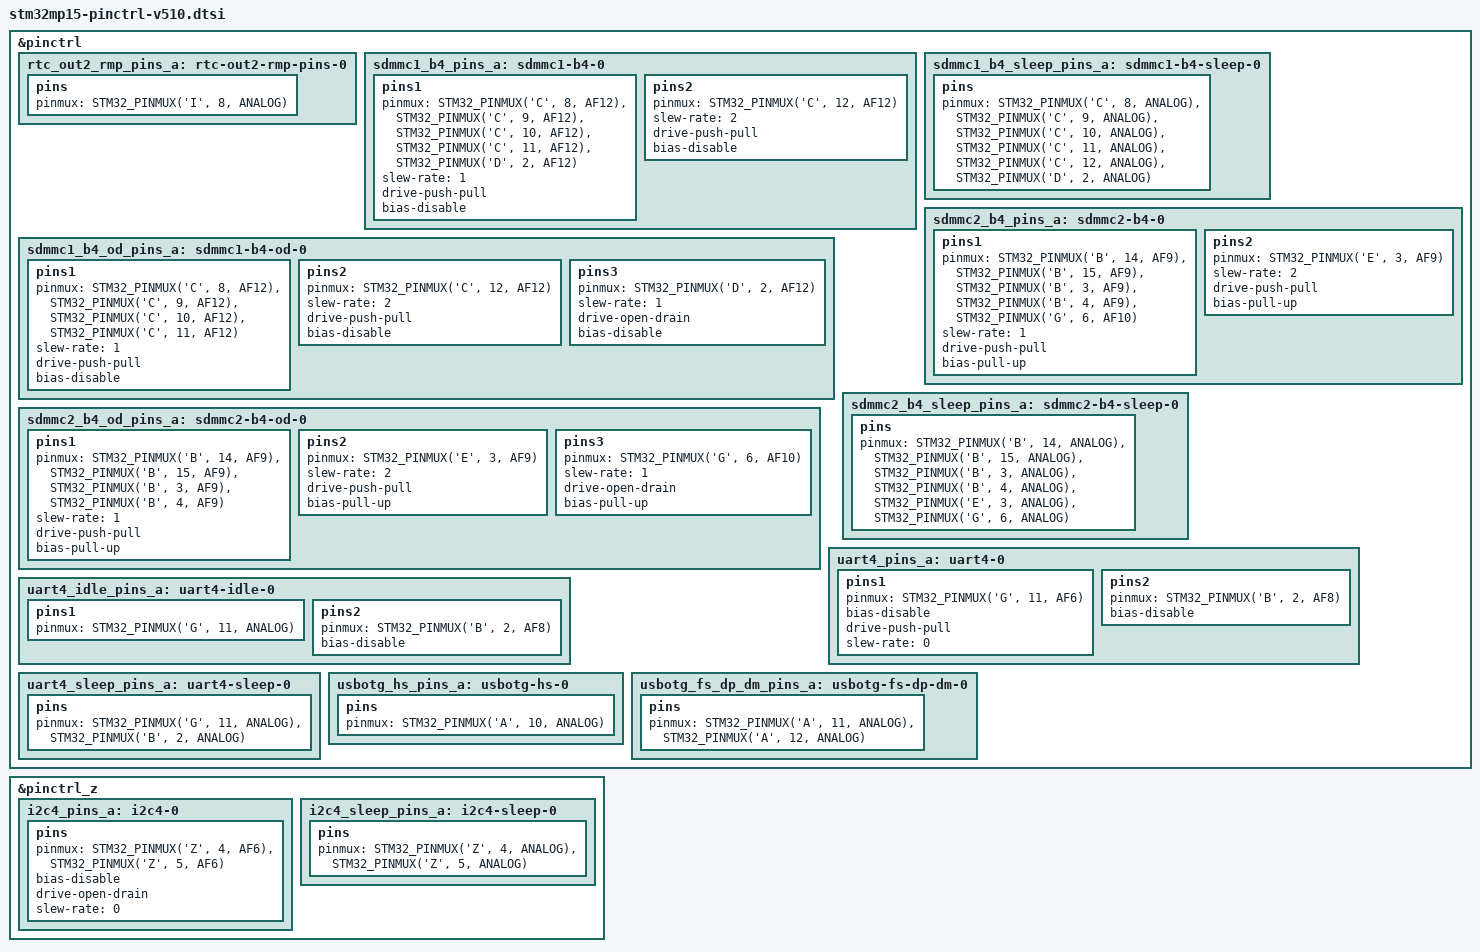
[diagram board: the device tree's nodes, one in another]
// SPDX-License-Identifier: (GPL-2.0+ OR BSD-3-Clause)
/*
 * Copyright (C) STMicroelectronics 2017 - All Rights Reserved
 * Author: Ludovic Barre <ludovic.barre@st.com> for STMicroelectronics.
 */
#include <dt-bindings/pinctrl/stm32-pinfunc.h>

&pinctrl {

	rtc_out2_rmp_pins_a: rtc-out2-rmp-pins-0 {
		pins {
			pinmux = <STM32_PINMUX('I', 8, ANALOG)>; /* RTC_OUT2_RMP */
		};
	};



	sdmmc1_b4_pins_a: sdmmc1-b4-0 {
		pins1 {
			pinmux = <STM32_PINMUX('C', 8, AF12)>, /* SDMMC1_D0 */
				 <STM32_PINMUX('C', 9, AF12)>, /* SDMMC1_D1 */
				 <STM32_PINMUX('C', 10, AF12)>, /* SDMMC1_D2 */
				 <STM32_PINMUX('C', 11, AF12)>, /* SDMMC1_D3 */
				 <STM32_PINMUX('D', 2, AF12)>; /* SDMMC1_CMD */
			slew-rate = <1>;
			drive-push-pull;
			bias-disable;
		};
		pins2 {
			pinmux = <STM32_PINMUX('C', 12, AF12)>; /* SDMMC1_CK */
			slew-rate = <2>;
			drive-push-pull;
			bias-disable;
		};
	};

	sdmmc1_b4_od_pins_a: sdmmc1-b4-od-0 {
		pins1 {
			pinmux = <STM32_PINMUX('C', 8, AF12)>, /* SDMMC1_D0 */
				 <STM32_PINMUX('C', 9, AF12)>, /* SDMMC1_D1 */
				 <STM32_PINMUX('C', 10, AF12)>, /* SDMMC1_D2 */
				 <STM32_PINMUX('C', 11, AF12)>; /* SDMMC1_D3 */
			slew-rate = <1>;
			drive-push-pull;
			bias-disable;
		};
		pins2 {
			pinmux = <STM32_PINMUX('C', 12, AF12)>; /* SDMMC1_CK */
			slew-rate = <2>;
			drive-push-pull;
			bias-disable;
		};
		pins3 {
			pinmux = <STM32_PINMUX('D', 2, AF12)>; /* SDMMC1_CMD */
			slew-rate = <1>;
			drive-open-drain;
			bias-disable;
		};
	};

	sdmmc1_b4_sleep_pins_a: sdmmc1-b4-sleep-0 {
		pins {
			pinmux = <STM32_PINMUX('C', 8, ANALOG)>, /* SDMMC1_D0 */
				 <STM32_PINMUX('C', 9, ANALOG)>, /* SDMMC1_D1 */
				 <STM32_PINMUX('C', 10, ANALOG)>, /* SDMMC1_D2 */
				 <STM32_PINMUX('C', 11, ANALOG)>, /* SDMMC1_D3 */
				 <STM32_PINMUX('C', 12, ANALOG)>, /* SDMMC1_CK */
				 <STM32_PINMUX('D', 2, ANALOG)>; /* SDMMC1_CMD */
		};
	};

	sdmmc2_b4_pins_a: sdmmc2-b4-0 {
		pins1 {
			pinmux = <STM32_PINMUX('B', 14, AF9)>, /* SDMMC2_D0 */
				 <STM32_PINMUX('B', 15, AF9)>, /* SDMMC2_D1 */
				 <STM32_PINMUX('B', 3, AF9)>, /* SDMMC2_D2 */
				 <STM32_PINMUX('B', 4, AF9)>, /* SDMMC2_D3 */
				 <STM32_PINMUX('G', 6, AF10)>; /* SDMMC2_CMD */
			slew-rate = <1>;
			drive-push-pull;
			bias-pull-up;
		};
		pins2 {
			pinmux = <STM32_PINMUX('E', 3, AF9)>; /* SDMMC2_CK */
			slew-rate = <2>;
			drive-push-pull;
			bias-pull-up;
		};
	};

	sdmmc2_b4_od_pins_a: sdmmc2-b4-od-0 {
		pins1 {
			pinmux = <STM32_PINMUX('B', 14, AF9)>, /* SDMMC2_D0 */
				 <STM32_PINMUX('B', 15, AF9)>, /* SDMMC2_D1 */
				 <STM32_PINMUX('B', 3, AF9)>, /* SDMMC2_D2 */
				 <STM32_PINMUX('B', 4, AF9)>; /* SDMMC2_D3 */
			slew-rate = <1>;
			drive-push-pull;
			bias-pull-up;
		};
		pins2 {
			pinmux = <STM32_PINMUX('E', 3, AF9)>; /* SDMMC2_CK */
			slew-rate = <2>;
			drive-push-pull;
			bias-pull-up;
		};
		pins3 {
			pinmux = <STM32_PINMUX('G', 6, AF10)>; /* SDMMC2_CMD */
			slew-rate = <1>;
			drive-open-drain;
			bias-pull-up;
		};
	};

	sdmmc2_b4_sleep_pins_a: sdmmc2-b4-sleep-0 {
		pins {
			pinmux = <STM32_PINMUX('B', 14, ANALOG)>, /* SDMMC2_D0 */
				 <STM32_PINMUX('B', 15, ANALOG)>, /* SDMMC2_D1 */
				 <STM32_PINMUX('B', 3, ANALOG)>, /* SDMMC2_D2 */
				 <STM32_PINMUX('B', 4, ANALOG)>, /* SDMMC2_D3 */
				 <STM32_PINMUX('E', 3, ANALOG)>, /* SDMMC2_CK */
				 <STM32_PINMUX('G', 6, ANALOG)>; /* SDMMC2_CMD */
		};
	};


	uart4_pins_a: uart4-0 {
		pins1 {
			pinmux = <STM32_PINMUX('G', 11, AF6)>; /* UART4_TX */
			bias-disable;
			drive-push-pull;
			slew-rate = <0>;
		};
		pins2 {
			pinmux = <STM32_PINMUX('B', 2, AF8)>; /* UART4_RX */
			bias-disable;
		};
	};

	uart4_idle_pins_a: uart4-idle-0 {
		pins1 {
			pinmux = <STM32_PINMUX('G', 11, ANALOG)>; /* UART4_TX */
		};
		pins2 {
			pinmux = <STM32_PINMUX('B', 2, AF8)>; /* UART4_RX */
			bias-disable;
		};
	};

	uart4_sleep_pins_a: uart4-sleep-0 {
		pins {
			pinmux = <STM32_PINMUX('G', 11, ANALOG)>, /* UART4_TX */
				 <STM32_PINMUX('B', 2, ANALOG)>; /* UART4_RX */
		};
	};

	usbotg_hs_pins_a: usbotg-hs-0 {
		pins {
			pinmux = <STM32_PINMUX('A', 10, ANALOG)>; /* OTG_ID */
		};
	};

	usbotg_fs_dp_dm_pins_a: usbotg-fs-dp-dm-0 {
		pins {
			pinmux = <STM32_PINMUX('A', 11, ANALOG)>, /* OTG_FS_DM */
				 <STM32_PINMUX('A', 12, ANALOG)>; /* OTG_FS_DP */
		};
	};
};

&pinctrl_z {

	i2c4_pins_a: i2c4-0 {
		pins {
			pinmux = <STM32_PINMUX('Z', 4, AF6)>, /* I2C4_SCL */
				 <STM32_PINMUX('Z', 5, AF6)>; /* I2C4_SDA */
			bias-disable;
			drive-open-drain;
			slew-rate = <0>;
		};
	};

	i2c4_sleep_pins_a: i2c4-sleep-0 {
		pins {
			pinmux = <STM32_PINMUX('Z', 4, ANALOG)>, /* I2C4_SCL */
				 <STM32_PINMUX('Z', 5, ANALOG)>; /* I2C4_SDA */
		};
	};
};
